# GD32F1x0 register map
File version: 1.0
CPU: CM3 r2p1, little endian, no MPU, no FPU, 4 interrupt priority bits
Registers are 32-bit, read-write, reset 0x0 unless marked. A register's access mark holds for its fields unless they carry their own. Offsets are from the block's base; [hi:lo] are bit positions.

## CEC — HDMI-CEC controller
Base 0x40007800
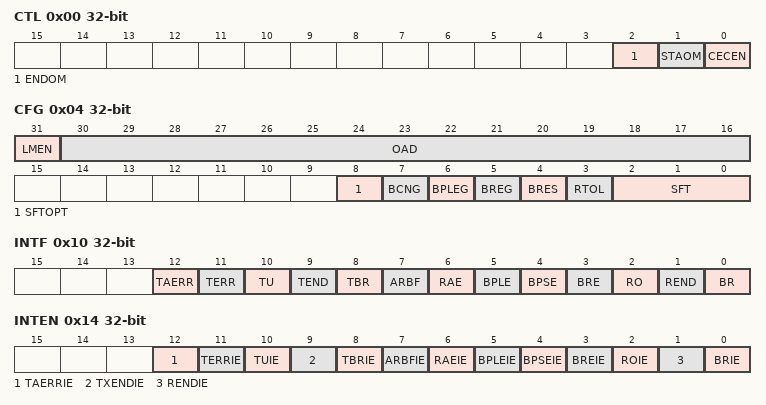
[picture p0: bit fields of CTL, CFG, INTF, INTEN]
0x00 CTL — control register
  [2] ENDOM — ENDOM bit value in the next frame in TX mode
  [1] STAOM — Start of sending a message
  [0] CECEN — Enable/disable HDMI-CEC controller
0x04 CFG — Configuration register
  [31] LMEN — Listen mode enable
  [30:16] OAD — Own Address
  [8] SFTOPT — The SFT start option
  [7] BCNG — Do not generate Error-bit in broadcast message
  [6] BPLEG — Generate Error-bit when detected RLBPE in singlecast
  [5] BREG — Generate Error-bit when detected RBRE in singlecast
  [4] BRES — Whether stop receive message when detected RBRE
  [3] RTOL — Reception bit timing tolerance
  [2:0] SFT — Signal Free Time
0x08 TDATA wo — Transmit data register
  [7:0] TDATA — Tx Data register
0x0C RDATA ro — Receive data register
  [7:0] RDATA
0x10 INTF — Interrupt Flag Register
  [12] TAERR — Tx ACK Error flag
  [11] TERR — Tx-Error
  [10] TU — Tx data buffer underrun
  [9] TEND — Transmission successfully end
  [8] TBR — Tx-Byte data request
  [7] ARBF — Arbitration fail
  [6] RAE — Rx ACK Error
  [5] BPLE — Bit Period Long Error
  [4] BPSE — Bit Period Short Error
  [3] BRE — Bit Rising Error
  [2] RO — RX Overrun
  [1] REND — End of Reception
  [0] BR — Byte received
0x14 INTEN — interrupt enable register
  [12] TAERRIE — TAERR Interrupt Enable
  [11] TERRIE — TERR Interrupt Enable
  [10] TUIE — TU Interrupt Enable
  [9] TXENDIE — TEND Interrupt Enable
  [8] TBRIE — TBR Interrupt Enable
  [7] ARBFIE — ARBF Interrupt Enable
  [6] RAEIE — RAE Interrupt Enable
  [5] BPLEIE — BPLE Interrupt Enable
  [4] BPSEIE — BPSE Interrupt Enable
  [3] BREIE — BRE Interrupt Enable
  [2] ROIE — RO Interrupt Enable
  [1] RENDIE — REND Interrupt Enable
  [0] BRIE — BR Interrupt Enable

## CMP — Comparator
Base 0x4001001C
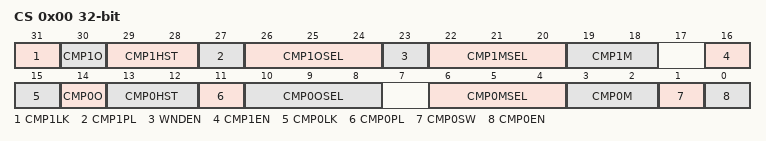
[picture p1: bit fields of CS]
0x00 CS access per field — control and status register
  [31] CMP1LK rw — CMP1 lock
  [30] CMP1O ro — CMP1 output
  [29:28] CMP1HST rw — CMP1 hysteresis
  [27] CMP1PL rw — Polarity of CMP1 output
  [26:24] CMP1OSEL rw — CMP1 output selection
  [23] WNDEN rw — Window mode enable
  [22:20] CMP1MSEL rw — CMP1_M input selection
  [19:18] CMP1M rw — CMP1 mode
  [16] CMP1EN rw — CMP1 enable
  [15] CMP0LK rw — CMP0 lock
  [14] CMP0O ro — CMP0 output
  [13:12] CMP0HST rw — CMP0 hysteresis
  [11] CMP0PL rw — Polarity of CMP0 output
  [10:8] CMP0OSEL rw — Comparator 0 output selection
  [6:4] CMP0MSEL rw — CMP0_M input selection
  [3:2] CMP0M rw — CMP0 mode
  [1] CMP0SW rw — CMP0 switch
  [0] CMP0EN rw — CMP0 enable

## CRC — cyclic redundancy check calculation unit
Base 0x40023000
0x00 DATA reset 0xFFFFFFFF
  [31:0] DATA — CRC calculation result
0x04 FDATA — Free data register
  [7:0] FDATA — Free Data Register bits
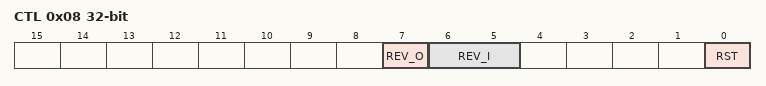
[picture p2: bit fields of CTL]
0x08 CTL — Control register
  [7] REV_O — Output Data Reverse Function
  [6:5] REV_I — Input Data Reverse Function
  [0] RST — reset bit
0x10 IDATA reset 0xFFFFFFFF — Initial CRC value
  [31:0] IDATA — Configurable initial CRC data value

## DAC — Digital-to-analog converter
Base 0x40007400
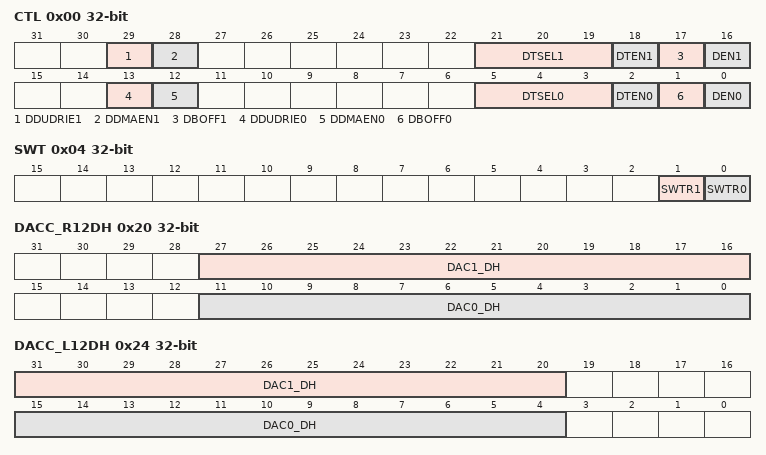
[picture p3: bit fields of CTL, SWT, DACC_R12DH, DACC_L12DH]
0x00 CTL — control register
  [29] DDUDRIE1 — DAC1 DMA Underrun Interrupt enable
  [28] DDMAEN1 — DAC1 DMA enable
  [21:19] DTSEL1 — DAC1 trigger selection
  [18] DTEN1 — DAC1 trigger enable
  [17] DBOFF1 — DAC1 output buffer turn off
  [16] DEN1 — DAC1 enable
  [13] DDUDRIE0 — DAC0 DMA Underrun Interrupt enable
  [12] DDMAEN0 — DAC0 DMA enable
  [5:3] DTSEL0 — DAC0 trigger selection
  [2] DTEN0 — DAC0 trigger enable
  [1] DBOFF0 — DAC0 output buffer turn off
  [0] DEN0 — DAC0 enable
0x04 SWT wo — software trigger register
  [1] SWTR1 — DAC1 software trigger
  [0] SWTR0 — DAC0 software trigger
0x08 DAC0_R12DH — DAC0 12-bit right-aligned data holding register
  [11:0] DAC0_DH — DAC0 12-bit right-aligned data
0x0C DAC0_L12DH — DAC0 12-bit left aligned data holding register
  [15:4] DAC0_DH — DAC0 12-bit left-aligned data
0x10 DAC0_R8DH — DAC0 8-bit right aligned data holding register
  [7:0] DAC0_DH — DAC0 8-bit right-aligned data
0x14 DAC1_R12DH — DAC1 12-bit right-aligned data holding register
  [11:0] DAC1_DH — DAC1 12-bit right-aligned data
0x18 DAC1_L12DH — DAC1 12-bit left aligned data holding register
  [15:4] DAC1_DH — DAC1 12-bit left-aligned data
0x1C DAC1_R8DH — DAC1 8-bit right aligned data holding register
  [7:0] DAC1_DH — DAC1 8-bit right-aligned data
0x20 DACC_R12DH — DAC concurrent mode 12-bit right-aligned data holding register
  [27:16] DAC1_DH — DAC1 12-bit right-aligned data
  [11:0] DAC0_DH — DAC0 12-bit right-aligned data
0x24 DACC_L12DH — DAC concurrent mode 12-bit left aligned data holding register
  [31:20] DAC1_DH — DAC1 12-bit left-aligned data
  [15:4] DAC0_DH — DAC0 12-bit left-aligned data
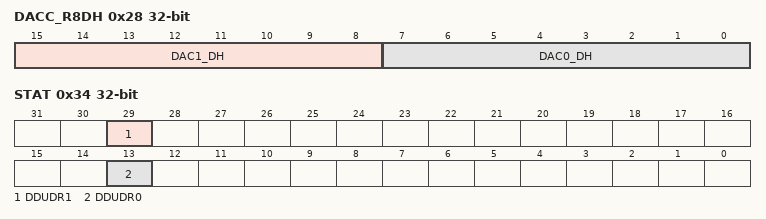
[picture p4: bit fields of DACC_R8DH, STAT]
0x28 DACC_R8DH — DAC concurrent mode 8-bit right aligned data holding register
  [15:8] DAC1_DH — DAC1 8-bit right-aligned data
  [7:0] DAC0_DH — DAC0 8-bit right-aligned data
0x2C DAC0_DO ro — DAC0 data output register
  [11:0] DAC0_DO — DAC0 output data
0x30 DAC1_DO ro — DAC1 data output register
  [11:0] DAC1_DO — DAC1 output data
0x34 STAT — status register
  [29] DDUDR1 — DAC1 DMA underrun flag
  [13] DDUDR0 — DAC0 DMA underrun flag
